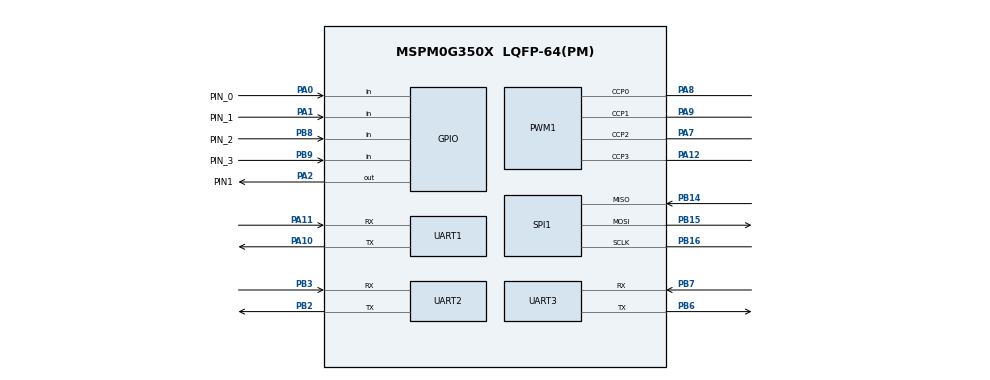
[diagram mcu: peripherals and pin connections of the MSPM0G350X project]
/**
 * @cliArgs --device "MSPM0G350X" --part "Default" --package "LQFP-64(PM)" --product "mspm0_sdk@2.04.00.06"
 * @versions {"tool":"1.21.1+3772"}
 */

/**
 * Import the modules used in this configuration.
 */
const GPIO    = scripting.addModule("/ti/driverlib/GPIO", {}, false);
const GPIO1   = GPIO.addInstance();
const GPIO2   = GPIO.addInstance();
const GPIO3   = GPIO.addInstance();
const GPIO4   = GPIO.addInstance();
const GPIO5   = GPIO.addInstance();
const GPIO6   = GPIO.addInstance();
const GPIO7   = GPIO.addInstance();
const GPIO8   = GPIO.addInstance();
const GPIO9   = GPIO.addInstance();
const GPIO10  = GPIO.addInstance();
const GPIO11  = GPIO.addInstance();
const GPIO12  = GPIO.addInstance();
const GPIO13  = GPIO.addInstance();
const PWM     = scripting.addModule("/ti/driverlib/PWM", {}, false);
const PWM1    = PWM.addInstance();
const SPI     = scripting.addModule("/ti/driverlib/SPI", {}, false);
const SPI1    = SPI.addInstance();
const SYSCTL  = scripting.addModule("/ti/driverlib/SYSCTL");
const SYSTICK = scripting.addModule("/ti/driverlib/SYSTICK");
const TIMER   = scripting.addModule("/ti/driverlib/TIMER", {}, false);
const TIMER1  = TIMER.addInstance();
const UART    = scripting.addModule("/ti/driverlib/UART", {}, false);
const UART1   = UART.addInstance();
const UART2   = UART.addInstance();
const UART3   = UART.addInstance();

/**
 * Write custom configuration values to the imported modules.
 */
const gate7  = system.clockTree["MFCLKGATE"];
gate7.enable = true;

GPIO1.$name                          = "BLK";
GPIO1.port                           = "PORTB";
GPIO1.associatedPins[0].$name        = "PIN_19";
GPIO1.associatedPins[0].initialValue = "SET";
GPIO1.associatedPins[0].assignedPin  = "19";

const Board = scripting.addModule("/ti/driverlib/Board", {}, false);

GPIO2.$name                         = "CS";
GPIO2.port                          = "PORTA";
GPIO2.associatedPins[0].$name       = "PIN_23";
GPIO2.associatedPins[0].assignedPin = "23";

GPIO3.$name                         = "DC";
GPIO3.port                          = "PORTB";
GPIO3.associatedPins[0].$name       = "PIN_24";
GPIO3.associatedPins[0].assignedPin = "24";

GPIO4.$name                         = "RES";
GPIO4.port                          = "PORTB";
GPIO4.associatedPins[0].$name       = "PIN_20";
GPIO4.associatedPins[0].assignedPin = "20";

GPIO5.$name                         = "MOSI";
GPIO5.port                          = "PORTA";
GPIO5.associatedPins[0].$name       = "PIN_28";
GPIO5.associatedPins[0].assignedPin = "28";

GPIO6.$name                         = "SCLK";
GPIO6.port                          = "PORTA";
GPIO6.associatedPins[0].$name       = "PIN_31";
GPIO6.associatedPins[0].assignedPin = "31";

GPIO7.$name                          = "CS1";
GPIO7.associatedPins[0].$name        = "PIN_17";
GPIO7.associatedPins[0].assignedPort = "PORTB";
GPIO7.associatedPins[0].assignedPin  = "17";

GPIO8.$name                              = "KEY";
GPIO8.port                               = "PORTA";
GPIO8.associatedPins.create(3);
GPIO8.associatedPins[0].$name            = "K1";
GPIO8.associatedPins[0].direction        = "INPUT";
GPIO8.associatedPins[0].internalResistor = "PULL_UP";
GPIO8.associatedPins[0].assignedPin      = "25";
GPIO8.associatedPins[1].$name            = "K2";
GPIO8.associatedPins[1].direction        = "INPUT";
GPIO8.associatedPins[1].internalResistor = "PULL_UP";
GPIO8.associatedPins[1].assignedPin      = "26";
GPIO8.associatedPins[2].$name            = "K3";
GPIO8.associatedPins[2].direction        = "INPUT";
GPIO8.associatedPins[2].internalResistor = "PULL_UP";
GPIO8.associatedPins[2].assignedPin      = "27";

GPIO9.$name                         = "LED";
GPIO9.port                          = "PORTB";
GPIO9.associatedPins[0].$name       = "LED1";
GPIO9.associatedPins[0].assignedPin = "18";

GPIO10.$name                         = "BEEP";
GPIO10.associatedPins[0].$name       = "PIN1";
GPIO10.associatedPins[0].pin.$assign = "PA2";

GPIO11.$name                         = "GPIO_Encoder_R";
GPIO11.associatedPins.create(2);
GPIO11.associatedPins[0].$name       = "PIN_0";
GPIO11.associatedPins[0].direction   = "INPUT";
GPIO11.associatedPins[0].interruptEn = true;
GPIO11.associatedPins[0].polarity    = "RISE";
GPIO11.associatedPins[0].pin.$assign = "PA0";
GPIO11.associatedPins[1].$name       = "PIN_1";
GPIO11.associatedPins[1].direction   = "INPUT";
GPIO11.associatedPins[1].interruptEn = true;
GPIO11.associatedPins[1].polarity    = "RISE";
GPIO11.associatedPins[1].pin.$assign = "PA1";

GPIO12.$name                         = "GPIO_Encoder_L";
GPIO12.associatedPins.create(2);
GPIO12.associatedPins[0].$name       = "PIN_2";
GPIO12.associatedPins[0].direction   = "INPUT";
GPIO12.associatedPins[0].interruptEn = true;
GPIO12.associatedPins[0].polarity    = "RISE";
GPIO12.associatedPins[0].pin.$assign = "PB8";
GPIO12.associatedPins[1].$name       = "PIN_3";
GPIO12.associatedPins[1].direction   = "INPUT";
GPIO12.associatedPins[1].interruptEn = true;
GPIO12.associatedPins[1].polarity    = "RISE";
GPIO12.associatedPins[1].pin.$assign = "PB9";

GPIO13.$name                         = "GREY";
GPIO13.port                          = "PORTA";
GPIO13.associatedPins.create(7);
GPIO13.associatedPins[0].$name       = "L3";
GPIO13.associatedPins[0].direction   = "INPUT";
GPIO13.associatedPins[0].assignedPin = "24";
GPIO13.associatedPins[1].$name       = "L2";
GPIO13.associatedPins[1].direction   = "INPUT";
GPIO13.associatedPins[1].assignedPin = "22";
GPIO13.associatedPins[2].$name       = "L1";
GPIO13.associatedPins[2].direction   = "INPUT";
GPIO13.associatedPins[2].assignedPin = "13";
GPIO13.associatedPins[3].$name       = "M";
GPIO13.associatedPins[3].direction   = "INPUT";
GPIO13.associatedPins[3].assignedPin = "17";
GPIO13.associatedPins[4].$name       = "R1";
GPIO13.associatedPins[4].direction   = "INPUT";
GPIO13.associatedPins[4].assignedPin = "16";
GPIO13.associatedPins[5].$name       = "R2";
GPIO13.associatedPins[5].direction   = "INPUT";
GPIO13.associatedPins[5].assignedPin = "15";
GPIO13.associatedPins[6].$name       = "R3";
GPIO13.associatedPins[6].direction   = "INPUT";
GPIO13.associatedPins[6].assignedPin = "14";

PWM1.$name                              = "PWM_Motor";
PWM1.clockDivider                       = 4;
PWM1.timerCount                         = 8000;
PWM1.pwmMode                            = "EDGE_ALIGN_UP";
PWM1.ccIndex                            = [0,1,2,3];
PWM1.peripheral.ccp0Pin.$assign         = "PA8";
PWM1.peripheral.ccp1Pin.$assign         = "PA9";
PWM1.peripheral.ccp2Pin.$assign         = "PA7";
PWM1.peripheral.ccp3Pin.$assign         = "PA12";
PWM1.PWM_CHANNEL_0.$name                = "ti_driverlib_pwm_PWMTimerCC0";
PWM1.PWM_CHANNEL_1.$name                = "ti_driverlib_pwm_PWMTimerCC1";
PWM1.ccp0PinConfig.direction            = scripting.forceWrite("OUTPUT");
PWM1.ccp0PinConfig.hideOutputInversion  = scripting.forceWrite(false);
PWM1.ccp0PinConfig.onlyInternalResistor = scripting.forceWrite(false);
PWM1.ccp0PinConfig.passedPeripheralType = scripting.forceWrite("Digital");
PWM1.ccp0PinConfig.$name                = "ti_driverlib_gpio_GPIOPinGeneric5";
PWM1.ccp1PinConfig.direction            = scripting.forceWrite("OUTPUT");
PWM1.ccp1PinConfig.hideOutputInversion  = scripting.forceWrite(false);
PWM1.ccp1PinConfig.onlyInternalResistor = scripting.forceWrite(false);
PWM1.ccp1PinConfig.passedPeripheralType = scripting.forceWrite("Digital");
PWM1.ccp1PinConfig.$name                = "ti_driverlib_gpio_GPIOPinGeneric6";
PWM1.PWM_CHANNEL_2.$name                = "ti_driverlib_pwm_PWMTimerCC2";
PWM1.PWM_CHANNEL_3.$name                = "ti_driverlib_pwm_PWMTimerCC3";
PWM1.ccp2PinConfig.$name                = "ti_driverlib_gpio_GPIOPinGeneric7";
PWM1.ccp3PinConfig.$name                = "ti_driverlib_gpio_GPIOPinGeneric8";

SPI1.$name                              = "SPI";
SPI1.targetBitRate                      = 16000000;
SPI1.frameFormat                        = "MOTO3";
SPI1.peripheral.$assign                 = "SPI1";
SPI1.peripheral.sclkPin.$assign         = "PB16";
SPI1.peripheral.mosiPin.$assign         = "PB15";
SPI1.peripheral.misoPin.$assign         = "PB14";
SPI1.sclkPinConfig.direction            = scripting.forceWrite("OUTPUT");
SPI1.sclkPinConfig.onlyInternalResistor = scripting.forceWrite(false);
SPI1.sclkPinConfig.passedPeripheralType = scripting.forceWrite("Digital");
SPI1.sclkPinConfig.$name                = "ti_driverlib_gpio_GPIOPinGeneric2";
SPI1.mosiPinConfig.direction            = scripting.forceWrite("OUTPUT");
SPI1.mosiPinConfig.hideOutputInversion  = scripting.forceWrite(false);
SPI1.mosiPinConfig.onlyInternalResistor = scripting.forceWrite(false);
SPI1.mosiPinConfig.passedPeripheralType = scripting.forceWrite("Digital");
SPI1.mosiPinConfig.$name                = "ti_driverlib_gpio_GPIOPinGeneric3";
SPI1.misoPinConfig.onlyInternalResistor = scripting.forceWrite(false);
SPI1.misoPinConfig.passedPeripheralType = scripting.forceWrite("Digital");
SPI1.misoPinConfig.$name                = "ti_driverlib_gpio_GPIOPinGeneric4";

SYSCTL.forceDefaultClkConfig = true;
SYSCTL.clockTreeEn           = true;

SYSTICK.periodEnable      = true;
SYSTICK.interruptPriority = "0";
SYSTICK.systickEnable     = true;
SYSTICK.period            = 32;

TIMER1.$name             = "TIMER_0";
TIMER1.timerClkDiv       = 8;
TIMER1.timerClkPrescale  = 256;
TIMER1.timerMode         = "PERIODIC_UP";
TIMER1.timerPeriod       = "1 ms";
TIMER1.timerStartTimer   = true;
TIMER1.interrupts        = ["LOAD"];
TIMER1.interruptPriority = "1";

UART1.$name                    = "UART_0";
UART1.uartClkSrc               = "MFCLK";
UART1.enabledInterrupts        = ["RX"];
UART1.targetBaudRate           = 115200;
UART1.peripheral.rxPin.$assign = "PA11";
UART1.peripheral.txPin.$assign = "PA10";
UART1.txPinConfig.$name        = "ti_driverlib_gpio_GPIOPinGeneric0";
UART1.rxPinConfig.$name        = "ti_driverlib_gpio_GPIOPinGeneric1";

UART2.enabledInterrupts                = ["RX"];
UART2.$name                            = "UART_3";
UART2.uartClkSrc                       = "MFCLK";
UART2.peripheral.$assign               = "UART3";
UART2.peripheral.rxPin.$assign         = "PB3";
UART2.peripheral.txPin.$assign         = "PB2";
UART2.txPinConfig.direction            = scripting.forceWrite("OUTPUT");
UART2.txPinConfig.hideOutputInversion  = scripting.forceWrite(false);
UART2.txPinConfig.onlyInternalResistor = scripting.forceWrite(false);
UART2.txPinConfig.passedPeripheralType = scripting.forceWrite("Digital");
UART2.txPinConfig.$name                = "ti_driverlib_gpio_GPIOPinGeneric9";
UART2.rxPinConfig.hideOutputInversion  = scripting.forceWrite(false);
UART2.rxPinConfig.onlyInternalResistor = scripting.forceWrite(false);
UART2.rxPinConfig.passedPeripheralType = scripting.forceWrite("Digital");
UART2.rxPinConfig.$name                = "ti_driverlib_gpio_GPIOPinGeneric10";

UART3.$name                            = "UART_1";
UART3.enabledInterrupts                = ["RX"];
UART3.targetBaudRate                   = 115200;
UART3.peripheral.rxPin.$assign         = "PB7";
UART3.peripheral.txPin.$assign         = "PB6";
UART3.txPinConfig.direction            = scripting.forceWrite("OUTPUT");
UART3.txPinConfig.hideOutputInversion  = scripting.forceWrite(false);
UART3.txPinConfig.onlyInternalResistor = scripting.forceWrite(false);
UART3.txPinConfig.passedPeripheralType = scripting.forceWrite("Digital");
UART3.txPinConfig.$name                = "ti_driverlib_gpio_GPIOPinGeneric11";
UART3.rxPinConfig.hideOutputInversion  = scripting.forceWrite(false);
UART3.rxPinConfig.onlyInternalResistor = scripting.forceWrite(false);
UART3.rxPinConfig.passedPeripheralType = scripting.forceWrite("Digital");
UART3.rxPinConfig.$name                = "ti_driverlib_gpio_GPIOPinGeneric12";

/**
 * Pinmux solution for unlocked pins/peripherals. This ensures that minor changes to the automatic solver in a future
 * version of the tool will not impact the pinmux you originally saw.  These lines can be completely deleted in order to
 * re-solve from scratch.
 */
GPIO1.associatedPins[0].pin.$suggestSolution  = "PB19";
Board.peripheral.$suggestSolution             = "DEBUGSS";
Board.peripheral.swclkPin.$suggestSolution    = "PA20";
Board.peripheral.swdioPin.$suggestSolution    = "PA19";
GPIO2.associatedPins[0].pin.$suggestSolution  = "PA23";
GPIO3.associatedPins[0].pin.$suggestSolution  = "PB24";
GPIO4.associatedPins[0].pin.$suggestSolution  = "PB20";
GPIO5.associatedPins[0].pin.$suggestSolution  = "PA28";
GPIO6.associatedPins[0].pin.$suggestSolution  = "PA31";
GPIO7.associatedPins[0].pin.$suggestSolution  = "PB17";
GPIO8.associatedPins[0].pin.$suggestSolution  = "PA25";
GPIO8.associatedPins[1].pin.$suggestSolution  = "PA26";
GPIO8.associatedPins[2].pin.$suggestSolution  = "PA27";
GPIO9.associatedPins[0].pin.$suggestSolution  = "PB18";
GPIO13.associatedPins[0].pin.$suggestSolution = "PA24";
GPIO13.associatedPins[1].pin.$suggestSolution = "PA22";
GPIO13.associatedPins[2].pin.$suggestSolution = "PA13";
GPIO13.associatedPins[3].pin.$suggestSolution = "PA17";
GPIO13.associatedPins[4].pin.$suggestSolution = "PA16";
GPIO13.associatedPins[5].pin.$suggestSolution = "PA15";
GPIO13.associatedPins[6].pin.$suggestSolution = "PA14";
PWM1.peripheral.$suggestSolution              = "TIMA0";
TIMER1.peripheral.$suggestSolution            = "TIMA1";
UART1.peripheral.$suggestSolution             = "UART0";
UART3.peripheral.$suggestSolution             = "UART1";
